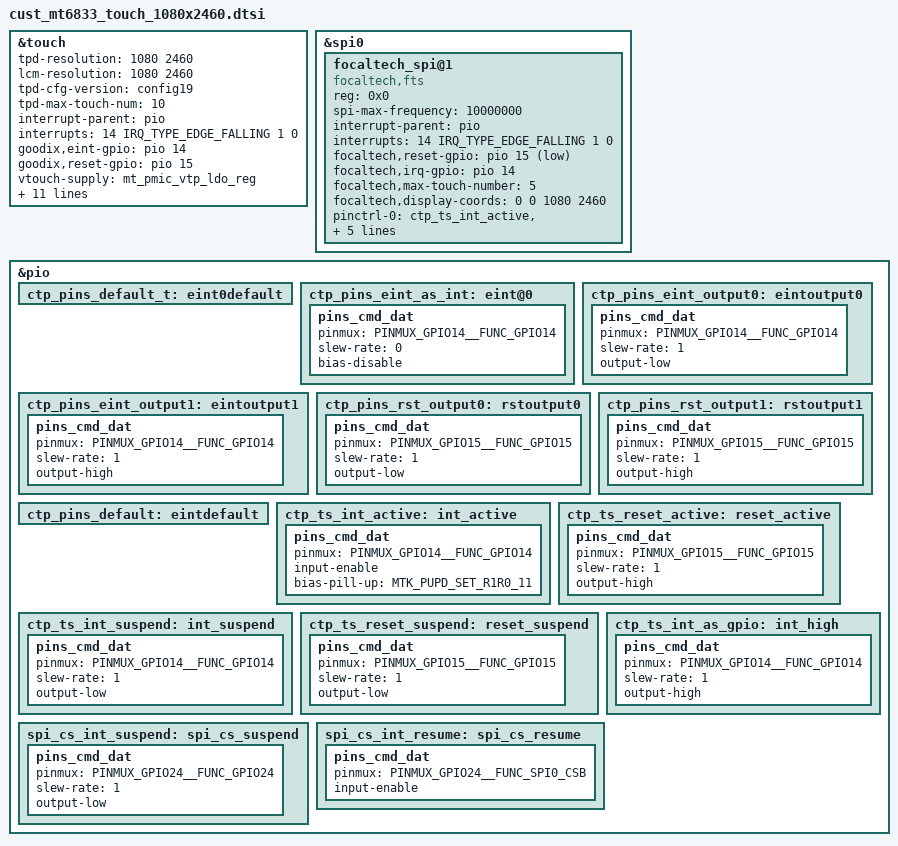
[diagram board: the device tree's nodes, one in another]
/*
 * Copyright (c) 2019 MediaTek Inc.
 *
 * This program is free software; you can redistribute it and/or modify
 * it under the terms of the GNU General Public License version 2 as
 * published by the Free Software Foundation.
 *
 * This program is distributed in the hope that it will be useful,
 * but WITHOUT ANY WARRANTY; without even the implied warranty of
 * MERCHANTABILITY or FITNESS FOR A PARTICULAR PURPOSE.  See the
 * GNU General Public License for more details.
 */
/* TOUCH start */
&touch {
	tpd-resolution = <1080 2460>;
	lcm-resolution = <1080 2460>;
	tpd-cfg-version = "config19";
	tpd-max-touch-num = <10>;
	interrupt-parent = <&pio>;
	interrupts = <14 IRQ_TYPE_EDGE_FALLING 1 0>;
	goodix,eint-gpio = <&pio 14 0x0>;
	goodix,reset-gpio = <&pio 15 0x0>;
	vtouch-supply = <&mt_pmic_vtp_ldo_reg>;

	/* Rotate cord when open blew lables */
	/*goodix,x2x;*/
	/*goodix,y2y;*/

	tpd-filter-enable = <0>;
	tpd-filter-pixel-density = <168>;
	tpd-filter-custom-prameters = <0 0 0 0 0 0 0 0 0 0 0 0>;
	tpd-filter-custom-speed = <0 0 0>;
	
	pinctrl-names = "default", "state_eint_as_int", "state_eint_output0",
		"state_eint_output1", "state_rst_output0", "state_rst_output1";
	pinctrl-0 = <&ctp_pins_default_t>;
	pinctrl-1 = <&ctp_pins_eint_as_int>;
	pinctrl-2 = <&ctp_pins_eint_output0>;
	pinctrl-3 = <&ctp_pins_eint_output1>;
	pinctrl-4 = <&ctp_pins_rst_output0>;
	pinctrl-5 = <&ctp_pins_rst_output1>;
	
	status = "okay";
};

&spi0 {
	focaltech_spi@1 {
		compatible = "focaltech,fts";
		reg = <0x0>;
		spi-max-frequency = <10000000>;
		interrupt-parent = <&pio>;
		//interrupts = <13 0x2>;
		interrupts = <14 IRQ_TYPE_EDGE_FALLING 1 0>;
		focaltech,reset-gpio = <&pio 15 0x01>; 
		focaltech,irq-gpio = <&pio 14 0x02>; 	
		focaltech,max-touch-number = <5>;			
		focaltech,display-coords =  <0 0 1080 2460>;
		
		pinctrl-names = "pmx_ts_active","pmx_ts_suspend", "spi_cs_suspend", "spi_cs_resume";  //prize add by wangfei for spi cs suspend and resume 20210617//,"pmx_ts_release";
		pinctrl-0 = <&ctp_ts_int_active &ctp_ts_reset_active>;
		pinctrl-1 = <&ctp_ts_int_suspend &ctp_ts_reset_suspend>;
		pinctrl-2 = <&spi_cs_int_suspend>;
		pinctrl-3 = <&spi_cs_int_resume>;
		status = "okay";

	};
};

&pio {
	ctp_pins_default_t: eint0default {
	};
	ctp_pins_eint_as_int: eint@0 {
		pins_cmd_dat {
			pinmux = <PINMUX_GPIO14__FUNC_GPIO14>;
			slew-rate = <0>;
			bias-disable;
		};
	};
	ctp_pins_eint_output0: eintoutput0 {
		pins_cmd_dat {
			pinmux = <PINMUX_GPIO14__FUNC_GPIO14>;
			slew-rate = <1>;
			output-low;
		};
	};
	ctp_pins_eint_output1: eintoutput1 {
		pins_cmd_dat {
			pinmux = <PINMUX_GPIO14__FUNC_GPIO14>;
			slew-rate = <1>;
			output-high;
		};
	};
	ctp_pins_rst_output0: rstoutput0 {
		pins_cmd_dat {
			pinmux = <PINMUX_GPIO15__FUNC_GPIO15>;
			slew-rate = <1>;
			output-low;
		};
	};
	ctp_pins_rst_output1: rstoutput1 {
		pins_cmd_dat {
			pinmux = <PINMUX_GPIO15__FUNC_GPIO15>;
			slew-rate = <1>;
			output-high;
		};
	};
};

&pio {
	ctp_pins_default: eintdefault {
	};
	ctp_ts_int_active: int_active {
		pins_cmd_dat {
			pinmux = <PINMUX_GPIO14__FUNC_GPIO14>;
			input-enable;
			bias-pill-up = <MTK_PUPD_SET_R1R0_11>;
		};
	};
	ctp_ts_reset_active: reset_active {
		pins_cmd_dat {
			pinmux = <PINMUX_GPIO15__FUNC_GPIO15>;
			slew-rate = <1>;
			output-high;
		};
	};
	ctp_ts_int_suspend: int_suspend {
		pins_cmd_dat {
			pinmux = <PINMUX_GPIO14__FUNC_GPIO14>;
			slew-rate = <1>;
			output-low;
		};
	};
	ctp_ts_reset_suspend: reset_suspend {
		pins_cmd_dat {
			pinmux = <PINMUX_GPIO15__FUNC_GPIO15>;
			slew-rate = <1>;
			output-low;
		};
	};
	ctp_ts_int_as_gpio: int_high {
		pins_cmd_dat {
			pinmux = <PINMUX_GPIO14__FUNC_GPIO14>;
			slew-rate = <1>;
			output-high;
		};
	};
//prize add by wangfei for tp spi cs suspend and resume pinctrl 20210617 start 
	spi_cs_int_suspend: spi_cs_suspend {
		pins_cmd_dat {
			pinmux = <PINMUX_GPIO24__FUNC_GPIO24>;
			slew-rate = <1>;
			output-low;
		};
	};

	spi_cs_int_resume: spi_cs_resume {
		pins_cmd_dat {
			pinmux = <PINMUX_GPIO24__FUNC_SPI0_CSB>;
			input-enable;
		};
	};
//prize add by wangfei for tp spi cs suspend and resume pinctrl 20210617 end
};
/* TOUCH end */
